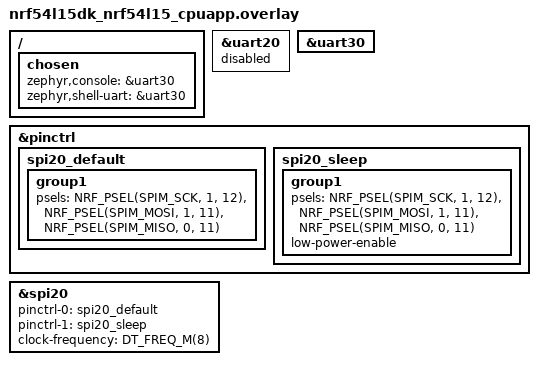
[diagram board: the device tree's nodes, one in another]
/*
 * Zephyr device tree overlay — Nordic nRF54L15-DK + EBYTE E22-900M30S (SX1262)
 *
 * Uses SPIM20 (peripheral domain SPI, flexible pin mapping).
 * SPIM00 is NOT used because its MISO pin (P2.09) conflicts with DK LED0.
 *
 * NOTE: uart20 and spi20 share hardware at 0xc6000 on nRF54L15.
 * The DK default DTS enables uart20; we disable it and enable spi20 instead.
 * UART30 (P0.00/P0.01) remains enabled for the debug console (IMCU VCOM).
 *
 * Physical wiring:
 *   E22 SCK  → P1.12
 *   E22 MOSI → P1.11
 *   E22 MISO → P0.11
 *   E22 NSS  → P0.09  (RadioLib GPIO, not hardware CS)
 *   E22 DIO1 → P0.08
 *   E22 BUSY → P0.07
 *   E22 RST  → P0.06
 *   E22 RXEN → P0.05  (held HIGH by SX126X_ANT_SW)
 */

/* Disable uart20 so that spi20 can use the shared peripheral at 0xc6000 */
&uart20 {
    status = "disabled";
};

/* Enable uart30 — IMCU VCOM debug console (P0.00 TX, P0.01 RX) */
&uart30 {
    status = "okay";
};

/ {
    chosen {
        zephyr,console = &uart30;
        zephyr,shell-uart = &uart30;
    };
};

&pinctrl {
    spi20_default: spi20_default {
        group1 {
            psels = <NRF_PSEL(SPIM_SCK,  1, 12)>,  /* P1.12 */
                    <NRF_PSEL(SPIM_MOSI, 1, 11)>,  /* P1.11 */
                    <NRF_PSEL(SPIM_MISO, 0, 11)>;  /* P0.11 */
        };
    };

    spi20_sleep: spi20_sleep {
        group1 {
            psels = <NRF_PSEL(SPIM_SCK,  1, 12)>,
                    <NRF_PSEL(SPIM_MOSI, 1, 11)>,
                    <NRF_PSEL(SPIM_MISO, 0, 11)>;
            low-power-enable;
        };
    };
};

&spi20 {
    status = "okay";
    pinctrl-0 = <&spi20_default>;
    pinctrl-1 = <&spi20_sleep>;
    pinctrl-names = "default", "sleep";
    clock-frequency = <DT_FREQ_M(8)>;  /* 8 MHz — safe for E22 over wires */

    /* CS and IRQ lines are bit-banged by RadioLib; no DT child node needed. */
};
